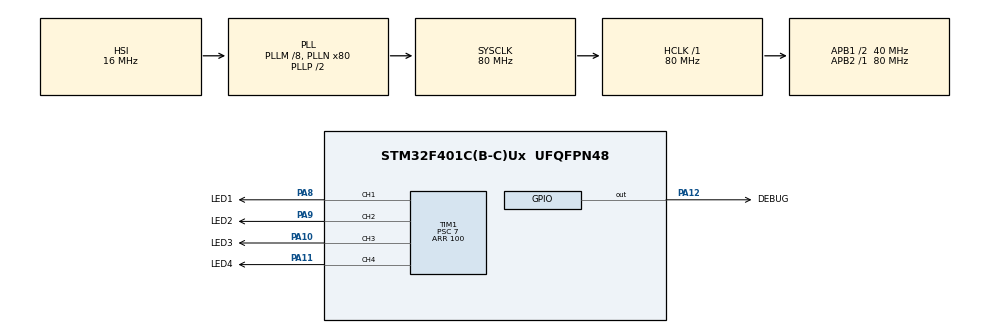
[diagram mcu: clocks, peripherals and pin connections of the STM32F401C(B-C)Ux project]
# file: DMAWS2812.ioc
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Dma.Request0=TIM1_UP
Dma.TIM1_UP.0.Direction=DMA_MEMORY_TO_PERIPH
Dma.TIM1_UP.0.FIFOMode=DMA_FIFOMODE_DISABLE
Dma.TIM1_UP.0.Instance=DMA2_Stream5
Dma.TIM1_UP.0.MemDataAlignment=DMA_MDATAALIGN_HALFWORD
Dma.TIM1_UP.0.MemInc=DMA_MINC_ENABLE
Dma.TIM1_UP.0.Mode=DMA_NORMAL
Dma.TIM1_UP.0.PeriphDataAlignment=DMA_PDATAALIGN_HALFWORD
Dma.TIM1_UP.0.PeriphInc=DMA_PINC_DISABLE
Dma.TIM1_UP.0.Priority=DMA_PRIORITY_VERY_HIGH
Mcu.Family=STM32F4
Mcu.Name=STM32F401C(B-C)Ux
Mcu.Package=UFQFPN48
NVIC.DMA2_Stream5_IRQn=true\:0\:0\:false\:false\:true\:false\:true
NVIC.PriorityGroup=NVIC_PRIORITYGROUP_4
NVIC.TIM1_CC_IRQn=true\:0\:0\:false\:false\:true\:true\:true
PA10.GPIO_Label=LED3
PA10.Signal=S_TIM1_CH3
PA11.GPIO_Label=LED4
PA11.Signal=S_TIM1_CH4
PA12.GPIO_Label=DEBUG
PA12.Signal=GPIO_Output
PA13.GPIO_Label=SWDIO
PA13.Mode=Serial_Wire
PA13.Signal=SYS_JTMS-SWDIO
PA14.GPIO_Label=SWCLK
PA14.Mode=Serial_Wire
PA14.Signal=SYS_JTCK-SWCLK
PA8.GPIO_Label=LED1
PA8.Signal=S_TIM1_CH1
PA9.GPIO_Label=LED2
PA9.Signal=S_TIM1_CH2
PH0\ -\ OSC_IN.Mode=HSE-External-Oscillator
PH0\ -\ OSC_IN.Signal=RCC_OSC_IN
PH1\ -\ OSC_OUT.Mode=HSE-External-Oscillator
PH1\ -\ OSC_OUT.Signal=RCC_OSC_OUT
ProjectManager.HeapSize=0x200
ProjectManager.StackSize=0x400
ProjectManager.TargetToolchain=STM32CubeIDE
RCC.48MHZClocksFreq_Value=40000000
RCC.AHBFreq_Value=80000000
RCC.APB1CLKDivider=RCC_HCLK_DIV2
RCC.APB1Freq_Value=40000000
RCC.APB1TimFreq_Value=80000000
RCC.APB2Freq_Value=80000000
RCC.APB2TimFreq_Value=80000000
RCC.CortexFreq_Value=80000000
RCC.HCLKFreq_Value=80000000
RCC.HSE_VALUE=25000000
RCC.HSI_VALUE=16000000
RCC.LSE_VALUE=32768
RCC.PLLM=8
RCC.PLLN=80
RCC.SYSCLKFreq_VALUE=80000000
RCC.SYSCLKSource=RCC_SYSCLKSOURCE_PLLCLK
RCC.VCOOutputFreq_Value=160000000
SH.S_TIM1_CH1.0=TIM1_CH1,PWM Generation1 CH1
SH.S_TIM1_CH2.0=TIM1_CH2,PWM Generation2 CH2
SH.S_TIM1_CH3.0=TIM1_CH3,PWM Generation3 CH3
SH.S_TIM1_CH4.0=TIM1_CH4,PWM Generation4 CH4
TIM1.Channel-PWM\ Generation1\ CH1=TIM_CHANNEL_1
TIM1.Channel-PWM\ Generation2\ CH2=TIM_CHANNEL_2
TIM1.Channel-PWM\ Generation3\ CH3=TIM_CHANNEL_3
TIM1.Channel-PWM\ Generation4\ CH4=TIM_CHANNEL_4
TIM1.OCFastMode_PWM-PWM\ Generation1\ CH1=TIM_OCFAST_ENABLE
TIM1.OCFastMode_PWM-PWM\ Generation2\ CH2=TIM_OCFAST_ENABLE
TIM1.OCFastMode_PWM-PWM\ Generation3\ CH3=TIM_OCFAST_ENABLE
TIM1.OCFastMode_PWM-PWM\ Generation4\ CH4=TIM_OCFAST_ENABLE
TIM1.Period=100
TIM1.Prescaler=7
VP_TIM1_VS_ClockSourceINT.Mode=Internal
board=custom

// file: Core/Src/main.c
/* USER CODE BEGIN Header */
/**
 ******************************************************************************
 * @file           : main.c
 * @brief          : Main program body
 ******************************************************************************
 * @attention
 *
 * <h2><center>&copy; Copyright (c) 2021 STMicroelectronics.
 * All rights reserved.</center></h2>
 *
 * This software component is licensed by ST under BSD 3-Clause license,
 * the "License"; You may not use this file except in compliance with the
 * License. You may obtain a copy of the License at:
 *                        opensource.org/licenses/BSD-3-Clause
 *
 ******************************************************************************
 */
/* USER CODE END Header */
#include "main.h"
#include "dma.h"
#include "tim.h"
#include "gpio.h"

/* USER CODE BEGIN Includes */
#include "User.h"
/* USER CODE END Includes */

void SystemClock_Config(void);

int main(void) {

	/* MCU Configuration--------------------------------------------------------*/

	/* Reset of all peripherals, Initializes the Flash interface and the Systick. */
	HAL_Init();

	/* Configure the system clock */
	SystemClock_Config();

	/* Initialize all configured peripherals */
	MX_GPIO_Init();
	MX_DMA_Init();
	MX_TIM1_Init();
	/* USER CODE BEGIN 2 */
	userMain();
	/* USER CODE END 2 */

	/* Infinite loop */
	while (1) {
		HAL_Delay(100);
	}
}

void SystemClock_Config(void) {
	RCC_OscInitTypeDef RCC_OscInitStruct = { 0 };
	RCC_ClkInitTypeDef RCC_ClkInitStruct = { 0 };

	/** Configure the main internal regulator output voltage
	 */
	__HAL_RCC_PWR_CLK_ENABLE();
	__HAL_PWR_VOLTAGESCALING_CONFIG(PWR_REGULATOR_VOLTAGE_SCALE2);
	/** Initializes the RCC Oscillators according to the specified parameters
	 * in the RCC_OscInitTypeDef structure.
	 */
	RCC_OscInitStruct.OscillatorType = RCC_OSCILLATORTYPE_HSI;
	RCC_OscInitStruct.HSIState = RCC_HSI_ON;
	RCC_OscInitStruct.HSICalibrationValue = RCC_HSICALIBRATION_DEFAULT;
	RCC_OscInitStruct.PLL.PLLState = RCC_PLL_ON;
	RCC_OscInitStruct.PLL.PLLSource = RCC_PLLSOURCE_HSI;
	RCC_OscInitStruct.PLL.PLLM = 8;
	RCC_OscInitStruct.PLL.PLLN = 80;
	RCC_OscInitStruct.PLL.PLLP = RCC_PLLP_DIV2;
	RCC_OscInitStruct.PLL.PLLQ = 4;
	if (HAL_RCC_OscConfig(&RCC_OscInitStruct) != HAL_OK) {
		Error_Handler();
	}
	/** Initializes the CPU, AHB and APB buses clocks
	 */
	RCC_ClkInitStruct.ClockType = RCC_CLOCKTYPE_HCLK | RCC_CLOCKTYPE_SYSCLK
			| RCC_CLOCKTYPE_PCLK1 | RCC_CLOCKTYPE_PCLK2;
	RCC_ClkInitStruct.SYSCLKSource = RCC_SYSCLKSOURCE_PLLCLK;
	RCC_ClkInitStruct.AHBCLKDivider = RCC_SYSCLK_DIV1;
	RCC_ClkInitStruct.APB1CLKDivider = RCC_HCLK_DIV2;
	RCC_ClkInitStruct.APB2CLKDivider = RCC_HCLK_DIV1;

	if (HAL_RCC_ClockConfig(&RCC_ClkInitStruct, FLASH_LATENCY_2) != HAL_OK) {
		Error_Handler();
	}
}

void Error_Handler(void) {
	__disable_irq();
	while (1) {
	}
}

/************************ (C) COPYRIGHT STMicroelectronics *****END OF FILE****/
